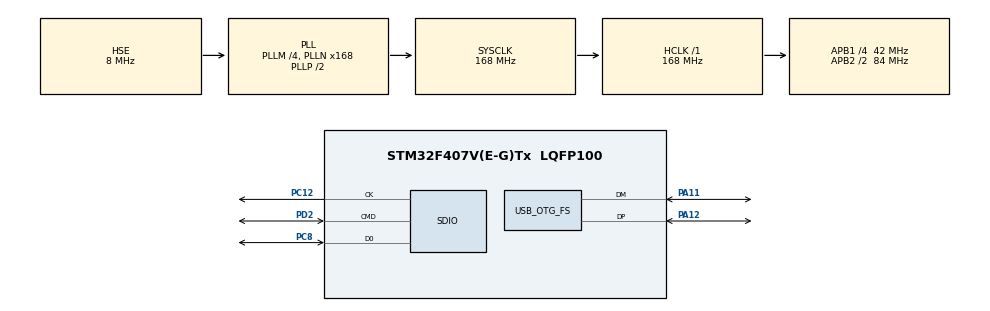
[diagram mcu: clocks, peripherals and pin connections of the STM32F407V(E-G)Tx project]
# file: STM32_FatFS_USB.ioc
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FATFS._USE_STRFUNC=1
Mcu.Family=STM32F4
Mcu.Name=STM32F407V(E-G)Tx
Mcu.Package=LQFP100
NVIC.OTG_FS_IRQn=true\:0\:0\:false\:false\:true\:false\:true
NVIC.PriorityGroup=NVIC_PRIORITYGROUP_4
PA11.Mode=Device_Only
PA11.Signal=USB_OTG_FS_DM
PA12.Mode=Device_Only
PA12.Signal=USB_OTG_FS_DP
PC12.GPIO_PuPd=GPIO_PULLDOWN
PC12.Mode=SD_1_bit
PC12.Signal=SDIO_CK
PC8.GPIO_PuPd=GPIO_PULLUP
PC8.Mode=SD_1_bit
PC8.Signal=SDIO_D0
PD2.GPIO_PuPd=GPIO_PULLUP
PD2.Mode=SD_1_bit
PD2.Signal=SDIO_CMD
PH0-OSC_IN.Mode=HSE-External-Oscillator
PH0-OSC_IN.Signal=RCC_OSC_IN
PH1-OSC_OUT.Mode=HSE-External-Oscillator
PH1-OSC_OUT.Signal=RCC_OSC_OUT
ProjectManager.HeapSize=0x200
ProjectManager.StackSize=0x400
ProjectManager.TargetToolchain=STM32CubeIDE
RCC.48MHZClocksFreq_Value=48000000
RCC.AHBFreq_Value=168000000
RCC.APB1CLKDivider=RCC_HCLK_DIV4
RCC.APB1Freq_Value=42000000
RCC.APB1TimFreq_Value=84000000
RCC.APB2CLKDivider=RCC_HCLK_DIV2
RCC.APB2Freq_Value=84000000
RCC.APB2TimFreq_Value=168000000
RCC.CortexFreq_Value=168000000
RCC.HCLKFreq_Value=168000000
RCC.HSE_VALUE=8000000
RCC.HSI_VALUE=16000000
RCC.LSE_VALUE=32768
RCC.PLLM=4
RCC.PLLN=168
RCC.PLLQ=7
RCC.SYSCLKFreq_VALUE=168000000
RCC.SYSCLKSource=RCC_SYSCLKSOURCE_PLLCLK
RCC.VCOOutputFreq_Value=336000000
USB_DEVICE.CLASS_NAME_FS=CDC
USB_DEVICE.USBD_MAX_STR_DESC_SIZ-CDC_FS=64000
USB_DEVICE.VirtualMode-CDC_FS=Cdc
USB_DEVICE.VirtualModeFS=Cdc_FS
USB_OTG_FS.VirtualMode=Device_Only
VP_FATFS_VS_SDIO.Mode=SDIO
VP_USB_DEVICE_VS_USB_DEVICE_CDC_FS.Mode=CDC_FS
board=custom

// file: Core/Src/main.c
/* USER CODE BEGIN Header */
/**
 ******************************************************************************
 * @file           : main.c
 * @brief          : Main program body
 ******************************************************************************
 * @attention
 *
 * Copyright (c) 2023 STMicroelectronics.
 * All rights reserved.
 *
 * This software is licensed under terms that can be found in the LICENSE file
 * in the root directory of this software component.
 * If no LICENSE file comes with this software, it is provided AS-IS.
 *
 ******************************************************************************
 */
/* USER CODE END Header */
#include "main.h"
#include "usb_device.h"
#include "usbd_cdc_if.h"

#include "../../AppDrivers/MSGPack/msg_pack.h"
#include "../../AppDrivers/SDCard/user_sd_card.h"
#include "../../AppDrivers/USB/usb_data.h"

/* USER CODE BEGIN PD */
#define TESTING

/* USER CODE END PD */

SD_HandleTypeDef hsd;
char receive_buffer[4096];
struct UsbDataReceived usb_data_received;

void SystemClock_Config(void);
static void MX_GPIO_Init(void);
static void MX_SDIO_SD_Init(void);

/* USER CODE BEGIN 0 */

void testing(SDcardTypeDef sdcard);

/* USER CODE END 0 */

int main(void) {

	/* MCU Configuration--------------------------------------------------------*/

	/* Reset of all peripherals, Initializes the Flash interface and the Systick. */
	HAL_Init();

	/* Configure the system clock */
	SystemClock_Config();

	/* Initialize all configured peripherals */
	MX_GPIO_Init();
	MX_SDIO_SD_Init();
	MX_FATFS_Init();
	MX_USB_DEVICE_Init();
	HAL_Delay(2000);

	// TODO: Exception control

	SDcardTypeDef sdcard;

#ifdef TESTING
	testing(sdcard);
#endif

	/* USER CODE END 2 */

	/* Infinite loop */
	/* USER CODE BEGIN WHILE */

	UINT size = 0;
	char data[1000] = { '\0' };
	char reading[1000] = { '\0' };

	usb_data_received.is_new_data = false;

	Mount_SD(&sdcard, "");
	MKDIR_SD(&sdcard, "logs\0"); // Create logs folder

	while (true) {
		if (usb_data_received.is_new_data) {

			// TODO: Extract the folder from the fileName

			if (usb_data_received.usb_data.command == WRITE) {

				if (sdcard.f_result == FR_OK) {
					CreateAndWriteFile_SD(&sdcard,
							usb_data_received.usb_data.fileName,
							usb_data_received.usb_data.content);
				}

			} else if (usb_data_received.usb_data.command == READ) {

				if (sdcard.f_result == FR_OK) {
					ReadFile_SD(&sdcard, usb_data_received.usb_data.fileName,
							reading, &size);
				}

				if (sdcard.f_result == FR_OK) {
					strncpy(usb_data_received.usb_data.content, reading,
							CONTENT_MAX_LENGHT);
				}

			} else if (usb_data_received.usb_data.command == DELETE) {

				if (sdcard.f_result == FR_OK) {
					EraseFile_SD(&sdcard, usb_data_received.usb_data.fileName);
				}

				if (sdcard.f_result == FR_OK) {
					strncpy(usb_data_received.usb_data.content, "Success\0",
							CONTENT_MAX_LENGHT);
				}

			} else if (usb_data_received.usb_data.command == UPDATE) {

				if (sdcard.f_result == FR_OK) {
					// TODO: update or erase content
					UpdateFile_SD(&sdcard, usb_data_received.usb_data.fileName,
							usb_data_received.usb_data.content);
				}

				if (sdcard.f_result == FR_OK) {
					ReadFile_SD(&sdcard, usb_data_received.usb_data.fileName,
							reading, &size);
				}

				if (sdcard.f_result == FR_OK) {
					strncpy(usb_data_received.usb_data.content, reading,
							CONTENT_MAX_LENGHT);
				}

			} else if (usb_data_received.usb_data.command == PRINT) {

				char path[256];
				path[0] = '\0';
				if (sdcard.f_result == FR_OK) {
					strncpy(path, "LOGS", 5);
					scan_files(&sdcard, path, &usb_data_received.usb_data);
					strncpy(usb_data_received.usb_data.fileName, "-",
							FILE_NAME_MAX_LENGHT);
				}

			} else {
				usb_data_received.usb_data.command = C_ERROR;
				break;
			}

			usb_data_received.is_new_data = false;

			// TODO: Create a usbDataToSend
			if (sdcard.f_result != FR_OK) {
				usb_data_received.usb_data.command = C_ERROR;
				strncpy(usb_data_received.usb_data.fileName, "-",
						FILE_NAME_MAX_LENGHT);
				strncpy(usb_data_received.usb_data.content, sdcard.message,
						CONTENT_MAX_LENGHT);
			}

			UnpackMSG(&usb_data_received.usb_data, data);

			size = strlen(data);
			CDC_Transmit_FS((uint8_t*) data, size);
			size = 0;
			memset(data, '\0');
			memset(reading, '\0');

			HAL_Delay(1);
		}

		/* USER CODE END WHILE */
		/* USER CODE BEGIN 3 */
	}

	Unmount_SD(&sdcard, "");
	/* USER CODE END 3 */
}

void SystemClock_Config(void) {
	RCC_OscInitTypeDef RCC_OscInitStruct = { 0 };
	RCC_ClkInitTypeDef RCC_ClkInitStruct = { 0 };

	/** Configure the main internal regulator output voltage
	 */
	__HAL_RCC_PWR_CLK_ENABLE();
	__HAL_PWR_VOLTAGESCALING_CONFIG(PWR_REGULATOR_VOLTAGE_SCALE1);

	/** Initializes the RCC Oscillators according to the specified parameters
	 * in the RCC_OscInitTypeDef structure.
	 */
	RCC_OscInitStruct.OscillatorType = RCC_OSCILLATORTYPE_HSE;
	RCC_OscInitStruct.HSEState = RCC_HSE_ON;
	RCC_OscInitStruct.PLL.PLLState = RCC_PLL_ON;
	RCC_OscInitStruct.PLL.PLLSource = RCC_PLLSOURCE_HSE;
	RCC_OscInitStruct.PLL.PLLM = 4;
	RCC_OscInitStruct.PLL.PLLN = 168;
	RCC_OscInitStruct.PLL.PLLP = RCC_PLLP_DIV2;
	RCC_OscInitStruct.PLL.PLLQ = 7;
	if (HAL_RCC_OscConfig(&RCC_OscInitStruct) != HAL_OK) {
		Error_Handler();
	}

	/** Initializes the CPU, AHB and APB buses clocks
	 */
	RCC_ClkInitStruct.ClockType = RCC_CLOCKTYPE_HCLK | RCC_CLOCKTYPE_SYSCLK
			| RCC_CLOCKTYPE_PCLK1 | RCC_CLOCKTYPE_PCLK2;
	RCC_ClkInitStruct.SYSCLKSource = RCC_SYSCLKSOURCE_PLLCLK;
	RCC_ClkInitStruct.AHBCLKDivider = RCC_SYSCLK_DIV1;
	RCC_ClkInitStruct.APB1CLKDivider = RCC_HCLK_DIV4;
	RCC_ClkInitStruct.APB2CLKDivider = RCC_HCLK_DIV2;

	if (HAL_RCC_ClockConfig(&RCC_ClkInitStruct, FLASH_LATENCY_5) != HAL_OK) {
		Error_Handler();
	}
}

static void MX_SDIO_SD_Init(void) {

	hsd.Instance = SDIO;
	hsd.Init.ClockEdge = SDIO_CLOCK_EDGE_RISING;
	hsd.Init.ClockBypass = SDIO_CLOCK_BYPASS_DISABLE;
	hsd.Init.ClockPowerSave = SDIO_CLOCK_POWER_SAVE_DISABLE;
	hsd.Init.BusWide = SDIO_BUS_WIDE_1B;
	hsd.Init.HardwareFlowControl = SDIO_HARDWARE_FLOW_CONTROL_DISABLE;
	hsd.Init.ClockDiv = 0;
}

static void MX_GPIO_Init(void) {
	GPIO_InitTypeDef GPIO_InitStruct = { 0 };

	/* GPIO Ports Clock Enable */
	__HAL_RCC_GPIOH_CLK_ENABLE();
	__HAL_RCC_GPIOA_CLK_ENABLE();
	__HAL_RCC_GPIOC_CLK_ENABLE();
	__HAL_RCC_GPIOD_CLK_ENABLE();

	/*Configure GPIO pin Output Level */
	HAL_GPIO_WritePin(GPIOA, GPIO_PIN_1, GPIO_PIN_RESET);

	/*Configure GPIO pin : PA1 */
	GPIO_InitStruct.Pin = GPIO_PIN_1;
	GPIO_InitStruct.Mode = GPIO_MODE_OUTPUT_PP;
	GPIO_InitStruct.Pull = GPIO_NOPULL;
	GPIO_InitStruct.Speed = GPIO_SPEED_FREQ_LOW;
	HAL_GPIO_Init(GPIOA, &GPIO_InitStruct);
}

/* USER CODE BEGIN 4 */

void testing(SDcardTypeDef sdcard) {
	char reading[1000] = "";
	UINT size = 0;
	Mount_SD(&sdcard, "");

	if (sdcard.f_result == FR_OK) {
		CreateAndWriteFile_SD(&sdcard, "file_1.txt",
				"Lorem ipsum dolor sit amet.\n");
	}

	if (sdcard.f_result == FR_OK) {
		CreateAndWriteFile_SD(&sdcard, "file_2.txt",
				"Lorem ipsum dolor sit amet.\n");
	}

	if (sdcard.f_result == FR_OK) {
		CreateAndWriteFile_SD(&sdcard, "23_04_2024.txt",
				"Lorem ipsum dolor sit amet.\n");
	}

	if (sdcard.f_result == FR_OK) {
		ReadFile_SD(&sdcard, "3.txt", reading, &size);
		HAL_Delay(1000);
		CDC_Transmit_FS((uint8_t*) reading, size);
		HAL_Delay(1);
	}

	if (sdcard.f_result == FR_OK) {
		UpdateFile_SD(&sdcard, "file_1.txt", "File created.\n");
	}

	if (sdcard.f_result == FR_OK) {
		UINT bytes = 0;
		ReadFile_SD(&sdcard, "file_1.txt", reading, &bytes);
	}

	if (sdcard.f_result == FR_OK) {
		EraseFile_SD(&sdcard, "file_2.txt");
	}

	MKDIR_SD(&sdcard, "folder");

	if (sdcard.f_result == FR_OK) {
		CreateAndWriteFile_SD(&sdcard, "folder/file_1.txt",
				"Folder created.\n");
	}

	Unmount_SD(&sdcard, "");
}
/* USER CODE END 4 */

void Error_Handler(void) {
	__disable_irq();
	while (1) {
	}
}
